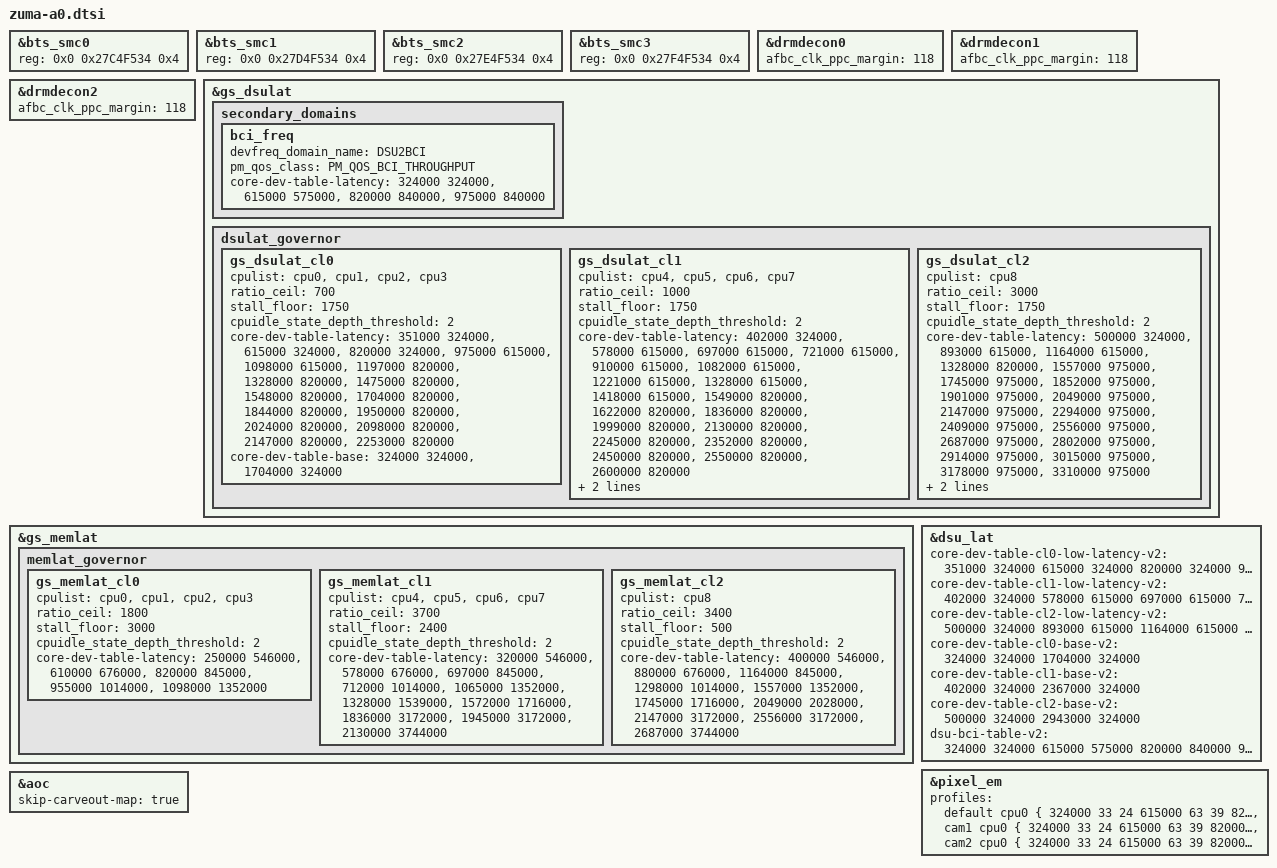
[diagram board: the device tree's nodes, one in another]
// SPDX-License-Identifier: GPL-2.0-only
/*
 * Copyright 2021 Google LLC.
 *
 */

#include "zuma.dtsi"

&bts_smc0 {
	reg = <0x0 0x27C4F534 0x4>;
};

&bts_smc1 {
	reg = <0x0 0x27D4F534 0x4>;
};

&bts_smc2 {
	reg = <0x0 0x27E4F534 0x4>;
};

&bts_smc3 {
	reg = <0x0 0x27F4F534 0x4>;
};

&drmdecon0 {
	afbc_clk_ppc_margin = <118>; /* additional 18% margin for afbc layer clock */
};

&drmdecon1 {
	afbc_clk_ppc_margin = <118>; /* additional 18% margin for afbc layer clock */
};

&drmdecon2 {
	afbc_clk_ppc_margin = <118>; /* additional 18% margin for afbc layer clock */
};

&gs_dsulat {
	/* Linearly Dependent Domains. */
	secondary_domains {
		bci_freq {
			devfreq_domain_name = "DSU2BCI";
			pm_qos_class = <PM_QOS_BCI_THROUGHPUT>;
			core-dev-table-latency =
			/* DSU     		BCI */
			< 324000        324000 >,
			< 615000        575000 >,
			< 820000        840000 >,
			< 975000        840000 >;
		};
	};

	dsulat_governor {
		gs_dsulat_cl0 {
			cpulist = <&cpu0>, <&cpu1>, <&cpu2>, <&cpu3>;
			ratio_ceil = <700>;
			stall_floor = <1750>;
			cpuidle_state_depth_threshold = <2>;

			core-dev-table-latency =
			/* CL0   DSU */
			< 351000        324000 >,
			< 615000        324000 >,
			< 820000        324000 >,
			< 975000        615000 >,
			< 1098000       615000 >,
			< 1197000       820000 >,
			< 1328000       820000 >,
			< 1475000       820000 >,
			< 1548000       820000 >,
			< 1704000       820000 >,
			< 1844000       820000 >,
			< 1950000       820000 >,
			< 2024000       820000 >,
			< 2098000       820000 >,
			< 2147000       820000 >,
			< 2253000       820000 >;

			core-dev-table-base =
			/* CL0    		DSU */
			<  324000        324000 >,
			< 1704000        324000 >;
		};
		gs_dsulat_cl1 {
			cpulist = <&cpu4>, <&cpu5>, <&cpu6>, <&cpu7>;
			ratio_ceil = <1000>;
			stall_floor = <1750>;
			cpuidle_state_depth_threshold = <2>;

			core-dev-table-latency =
			/* CL1    		DSU */
			< 402000        324000 >,
			< 578000        615000 >,
			< 697000        615000 >,
			< 721000        615000 >,
			< 910000        615000 >,
			< 1082000       615000 >,
			< 1221000       615000 >,
			< 1328000       615000 >,
			< 1418000       615000 >,
			< 1549000       820000 >,
			< 1622000       820000 >,
			< 1836000       820000 >,
			< 1999000       820000 >,
			< 2130000       820000 >,
			< 2245000       820000 >,
			< 2352000       820000 >,
			< 2450000       820000 >,
			< 2550000       820000 >,
			< 2600000       820000 >;

			core-dev-table-base =
			/* CL1    		DSU */
			<  402000       324000 >,
			< 2367000       324000 >;

		};
		gs_dsulat_cl2 {
			cpulist = <&cpu8>;
			ratio_ceil = <3000>;
			stall_floor = <1750>;
			cpuidle_state_depth_threshold = <2>;

			core-dev-table-latency =
			/* CL2    		DSU */
			< 500000        324000 >,
			< 893000        615000 >,
			< 1164000       615000 >,
			< 1328000       820000 >,
			< 1557000       975000 >,
			< 1745000       975000 >,
			< 1852000       975000 >,
			< 1901000       975000 >,
			< 2049000       975000 >,
			< 2147000       975000 >,
			< 2294000       975000 >,
			< 2409000       975000 >,
			< 2556000       975000 >,
			< 2687000       975000 >,
			< 2802000       975000 >,
			< 2914000       975000 >,
			< 3015000       975000 >,
			< 3178000       975000 >,
			< 3310000       975000 >;

			core-dev-table-base =
			/* CL2    DSU */
			<  500000       324000 >,
			< 2943000       324000 >;
		};
	};
};

&gs_memlat {
	memlat_governor {
		gs_memlat_cl0 {
			cpulist = <&cpu0>, <&cpu1>, <&cpu2>, <&cpu3>;
			ratio_ceil = <1800>;
			stall_floor = <3000>;
			cpuidle_state_depth_threshold = <2>;

			core-dev-table-latency =
			/* CL0         MIF */
			<  250000  546000 >,
			<  610000  676000 >,
			<  820000  845000 >,
			<  955000 1014000 >,
			< 1098000 1352000 >;
		};
		gs_memlat_cl1 {
			cpulist = <&cpu4>, <&cpu5>, <&cpu6>, <&cpu7>;
			ratio_ceil = <3700>;
			stall_floor = <2400>;
			cpuidle_state_depth_threshold = <2>;

			core-dev-table-latency =
			/* CL1         MIF */
			<  320000  546000 >,
			<  578000  676000 >,
			<  697000  845000 >,
			<  712000 1014000 >,
			< 1065000 1352000 >,
			< 1328000 1539000 >,
			< 1572000 1716000 >,
			< 1836000 3172000 >,
			< 1945000 3172000 >,
			< 2130000 3744000 >;
		};
		gs_memlat_cl2 {
			cpulist = <&cpu8>;
			ratio_ceil = <3400>;
			stall_floor = <500>;
			cpuidle_state_depth_threshold = <2>;

			core-dev-table-latency =
			/* CL2         MIF */
			<  400000  546000 >,
			<  880000  676000 >,
			< 1164000  845000 >,
			< 1298000 1014000 >,
			< 1557000 1352000 >,
			< 1745000 1716000 >,
			< 2049000 2028000 >,
			< 2147000 3172000 >,
			< 2556000 3172000 >,
			< 2687000 3744000 >;
		};
	};
};

&dsu_lat {
	core-dev-table-cl0-low-latency-v2 =
		/* CL0         DSU */
		< 351000        324000
		615000        324000
		820000        324000
		975000        615000
		1098000       615000
		1197000       820000
		1328000       820000
		1475000       820000
		1548000       820000
		1704000       820000
		1844000       820000
		1950000       820000
		2024000       820000
		2098000       820000
		2147000       820000
		2253000       820000 >;

	core-dev-table-cl1-low-latency-v2 =
		/* CL1         DSU */
		< 402000        324000
		578000        615000
		697000        615000
		721000        615000
		910000        615000
		1082000       615000
		1221000       615000
		1328000       615000
		1418000       615000
		1549000       820000
		1622000       820000
		1836000       820000
		1999000       820000
		2130000       820000
		2245000       820000
		2352000       820000
		2450000       820000
		2550000       820000
		2600000       820000 >;

	core-dev-table-cl2-low-latency-v2 =
		/* CL2         DSU */
		< 500000        324000
		893000        615000
		1164000       615000
		1328000       820000
		1557000       975000
		1745000       975000
		1852000       975000
		1901000       975000
		2049000       975000
		2147000       975000
		2294000       975000
		2409000       975000
		2556000       975000
		2687000       975000
		2802000       975000
		2914000       975000
		3015000       975000
		3178000       975000
		3310000       975000 >;

	core-dev-table-cl0-base-v2 =
		<  324000        324000
		  1704000        324000 >;

	core-dev-table-cl1-base-v2 =
		<  402000       324000
		  2367000       324000 >;

	core-dev-table-cl2-base-v2 =
		<  500000       324000
		  2943000       324000 >;

	dsu-bci-table-v2 =
		/* DSU         BCI */
		< 324000        324000
		615000        575000
		820000        840000
		975000        840000 >;
};

&pixel_em {
		profiles =
			"default
				cpu0 {
				324000 33 24
				615000 63 39
				820000 84 56
				975000 100 73
				1098000 113 86
				1197000 123 98
				1328000 136 116
				1475000 152 141
				1548000 159 158
				1704000 175 198
				1844000 189 242
				1950000 201 289
				2024000 208 328
				2098000 216 370
				2147000 220 396
				}
				cpu4 {
				402000 118 56
				578000 170 84
				697000 205 105
				721000 212 107
				910000 268 148
				1082000 318 201
				1221000 359 251
				1328000 405 304
				1418000 439 356
				1549000 456 405
				1622000 478 439
				1836000 540 596
				1999000 588 743
				2130000 629 930
				2245000 661 1122
				2352000 692 1314
				2450000 721 1515
				}
				cpu8 {
				500000 171 121
				893000 288 225
				1164000 399 342
				1328000 443 415
				1557000 507 544
				1745000 571 682
				1852000 609 765
				1901000 618 799
				2049000 680 983
				2147000 714 1134
				2294000 748 1322
				2409000 794 1481
				2556000 850 1883
				2687000 923 2377
				2802000 972 2882
				2914000 999 3465
				3015000 1024 3954
				}
			",
			"cam1
				cpu0 {
				324000 33 24
				615000 63 39
				820000 84 56
				975000 100 73
				1098000 113 86
				1197000 123 98
				1328000 136 116
				1475000 152 141
				1548000 159 158
				1704000 175 198
				1844000 189 242
				1950000 201 289
				2024000 208 328
				2098000 216 370
				2147000 220 396
				}
				cpu4 {
				402000 118 56
				578000 170 84
				697000 205 105
				721000 212 107
				910000 268 148
				1082000 318 201
				1221000 359 251
				1328000 405 304
				1418000 439 356
				1549000 456 405
				1622000 478 439
				1836000 540 596
				1999000 588 743
				2130000 629 930
				2245000 661 1122
				2352000 692 1314
				2450000 721 1515
				}
				cpu8 {
				500000 171 121
				893000 288 225
				1164000 399 342
				1328000 443 415
				1557000 507 544
				1745000 571 682
				1852000 609 765
				1901000 618 799
				2049000 680 983
				2147000 714 1134
				2294000 748 1322
				2409000 794 1481
				2556000 850 1883
				2687000 923 2377
				2802000 972 2882
				2914000 999 3465
				3015000 1024 3954
				}
			",
			"cam2
				cpu0 {
				324000 33 24
				615000 63 39
				820000 84 56
				975000 100 73
				1098000 113 86
				1197000 123 98
				1328000 136 116
				1475000 152 141
				1548000 159 158
				1704000 175 198
				1844000 189 242
				1950000 201 289
				2024000 208 328
				2098000 216 370
				2147000 220 396
				}
				cpu4 {
				402000 118 56
				578000 170 84
				697000 205 105
				721000 212 107
				910000 268 148
				1082000 318 201
				1221000 359 251
				1328000 405 304
				1418000 439 356
				1549000 456 405
				1622000 478 439
				1836000 540 596
				1999000 588 743
				2130000 629 930
				2245000 661 1122
				2352000 692 1314
				2450000 721 1515
				}
				cpu8 {
				500000 171 121
				893000 288 225
				1164000 399 342
				1328000 443 415
				1557000 507 544
				1745000 571 682
				1852000 609 765
				1901000 618 799
				2049000 680 983
				2147000 714 1134
				2294000 748 1322
				2409000 794 1481
				2556000 850 1883
				2687000 923 2377
				2802000 972 2882
				2914000 999 3465
				3015000 1024 3954
				}
			";
};

&aoc {
	skip-carveout-map = "true";
};
